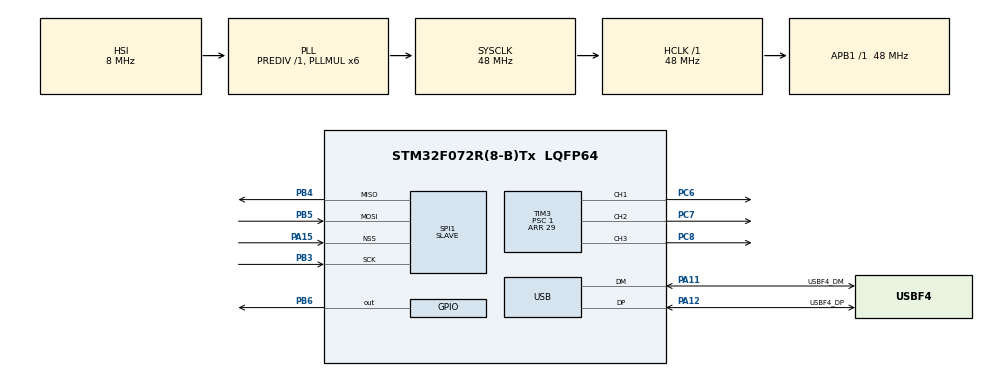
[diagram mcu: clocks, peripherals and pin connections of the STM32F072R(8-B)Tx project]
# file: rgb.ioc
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Dma.Request0=SPI1_TX
Dma.SPI1_TX.0.Direction=DMA_MEMORY_TO_PERIPH
Dma.SPI1_TX.0.Instance=DMA1_Channel3
Dma.SPI1_TX.0.MemDataAlignment=DMA_MDATAALIGN_BYTE
Dma.SPI1_TX.0.MemInc=DMA_MINC_ENABLE
Dma.SPI1_TX.0.Mode=DMA_NORMAL
Dma.SPI1_TX.0.PeriphDataAlignment=DMA_PDATAALIGN_BYTE
Dma.SPI1_TX.0.PeriphInc=DMA_PINC_DISABLE
Dma.SPI1_TX.0.Priority=DMA_PRIORITY_LOW
Mcu.Family=STM32F0
Mcu.Name=STM32F072R(8-B)Tx
Mcu.Package=LQFP64
NVIC.DMA1_Channel2_3_IRQn=true\:0\:0\:false\:false\:true\:false
NVIC.USB_IRQn=true\:0\:0\:false\:false\:true\:false
PA11.GPIO_Label=USBF4_DM
PA11.Mode=Device
PA11.Signal=USB_DM
PA12.GPIO_Label=USBF4_DP
PA12.Mode=Device
PA12.Signal=USB_DP
PA13.GPIO_Label=SWDIO
PA13.Mode=Serial_Wire
PA13.Signal=SYS_SWDIO
PA14.GPIO_Label=SWCLK
PA14.Mode=Serial_Wire
PA14.Signal=SYS_SWCLK
PA15.GPIO_PuPd=GPIO_PULLDOWN
PA15.Mode=NSS_Signal_Hard_Input
PA15.Signal=SPI1_NSS
PB3.Mode=Full_Duplex_Slave
PB3.Signal=SPI1_SCK
PB4.Mode=Full_Duplex_Slave
PB4.Signal=SPI1_MISO
PB5.Mode=Full_Duplex_Slave
PB5.Signal=SPI1_MOSI
PB6.Signal=GPIO_Output
PC6.Signal=S_TIM3_CH1
PC7.Signal=S_TIM3_CH2
PC8.Signal=S_TIM3_CH3
ProjectManager.HeapSize=0x1000
ProjectManager.StackSize=0x1000
ProjectManager.TargetToolchain=TrueSTUDIO
RCC.AHBFreq_Value=48000000
RCC.APB1Freq_Value=48000000
RCC.APB1TimFreq_Value=48000000
RCC.HCLKFreq_Value=48000000
RCC.PLLMUL=RCC_PLL_MUL6
RCC.SYSCLKFreq_VALUE=48000000
RCC.SYSCLKSource=RCC_SYSCLKSOURCE_PLLCLK
SH.S_TIM3_CH1.0=TIM3_CH1,PWM Generation1 CH1
SH.S_TIM3_CH2.0=TIM3_CH2,PWM Generation2 CH2
SH.S_TIM3_CH3.0=TIM3_CH3,PWM Generation3 CH3
SPI1.Direction=SPI_DIRECTION_2LINES
SPI1.Mode=SPI_MODE_SLAVE
SPI1.VirtualNSS=VM_NSSHARD
SPI1.VirtualType=VM_SLAVE
TIM3.Channel-PWM\ Generation1\ CH1=TIM_CHANNEL_1
TIM3.Channel-PWM\ Generation2\ CH2=TIM_CHANNEL_2
TIM3.Channel-PWM\ Generation3\ CH3=TIM_CHANNEL_3
TIM3.Period=29
TIM3.Prescaler=1
TIM3.Pulse-PWM\ Generation1\ CH1=14
TIM3.Pulse-PWM\ Generation2\ CH2=8
TIM3.Pulse-PWM\ Generation3\ CH3=22
USB.phy_itface=PCD_PHY_EMBEDDED
USB.speed=PCD_SPEED_FULL
USB_DEVICE.CLASS_NAME_FS=CDC
USB_DEVICE.VirtualMode=Cdc
USB_DEVICE.VirtualModeFS=Cdc_FS
VP_TIM3_VS_ClockSourceINT.Mode=Internal
VP_USB_DEVICE_VS_USB_DEVICE_CDC_FS.Mode=CDC_FS
board=32F072BDISCOVERY

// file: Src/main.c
/**
  ******************************************************************************
  * @file           : main.c
  * @brief          : Main program body
  ******************************************************************************
  * This notice applies to any and all portions of this file
  * that are not between comment pairs USER CODE BEGIN and
  * USER CODE END. Other portions of this file, whether
  * inserted by the user or by software development tools
  * are owned by their respective copyright owners.
  *
  * Copyright (c) 2019 STMicroelectronics International N.V.
  * All rights reserved.
  *
  * Redistribution and use in source and binary forms, with or without
  * modification, are permitted, provided that the following conditions are met:
  *
  * 1. Redistribution of source code must retain the above copyright notice,
  *    this list of conditions and the following disclaimer.
  * 2. Redistributions in binary form must reproduce the above copyright notice,
  *    this list of conditions and the following disclaimer in the documentation
  *    and/or other materials provided with the distribution.
  * 3. Neither the name of STMicroelectronics nor the names of other
  *    contributors to this software may be used to endorse or promote products
  *    derived from this software without specific written permission.
  * 4. This software, including modifications and/or derivative works of this
  *    software, must execute solely and exclusively on microcontroller or
  *    microprocessor devices manufactured by or for STMicroelectronics.
  * 5. Redistribution and use of this software other than as permitted under
  *    this license is void and will automatically terminate your rights under
  *    this license.
  *
  * THIS SOFTWARE IS PROVIDED BY STMICROELECTRONICS AND CONTRIBUTORS "AS IS"
  * AND ANY EXPRESS, IMPLIED OR STATUTORY WARRANTIES, INCLUDING, BUT NOT
  * LIMITED TO, THE IMPLIED WARRANTIES OF MERCHANTABILITY, FITNESS FOR A
  * PARTICULAR PURPOSE AND NON-INFRINGEMENT OF THIRD PARTY INTELLECTUAL PROPERTY
  * RIGHTS ARE DISCLAIMED TO THE FULLEST EXTENT PERMITTED BY LAW. IN NO EVENT
  * SHALL STMICROELECTRONICS OR CONTRIBUTORS BE LIABLE FOR ANY DIRECT, INDIRECT,
  * INCIDENTAL, SPECIAL, EXEMPLARY, OR CONSEQUENTIAL DAMAGES (INCLUDING, BUT NOT
  * LIMITED TO, PROCUREMENT OF SUBSTITUTE GOODS OR SERVICES; LOSS OF USE, DATA,
  * OR PROFITS; OR BUSINESS INTERRUPTION) HOWEVER CAUSED AND ON ANY THEORY OF
  * LIABILITY, WHETHER IN CONTRACT, STRICT LIABILITY, OR TORT (INCLUDING
  * NEGLIGENCE OR OTHERWISE) ARISING IN ANY WAY OUT OF THE USE OF THIS SOFTWARE,
  * EVEN IF ADVISED OF THE POSSIBILITY OF SUCH DAMAGE.
  *
  ******************************************************************************
  */
#include "main.h"
#include "stm32f0xx_hal.h"
#include "usb_device.h"

/* USER CODE BEGIN Includes */
#include "ws2812_if.h"
/* USER CODE END Includes */

SPI_HandleTypeDef hspi1;
DMA_HandleTypeDef hdma_spi1_tx;

TIM_HandleTypeDef htim3;

/* USER CODE BEGIN PV */
/* Private variables ---------------------------------------------------------*/

/* USER CODE END PV */

void SystemClock_Config(void);
static void MX_GPIO_Init(void);
static void MX_DMA_Init(void);
static void MX_SPI1_Init(void);
static void MX_TIM3_Init(void);

void HAL_TIM_MspPostInit(TIM_HandleTypeDef *htim);

/* USER CODE BEGIN PFP */
/* Private function prototypes -----------------------------------------------*/

  /* USER CODE END DMA1_Channel2_3_IRQn 0 */

  /* USER CODE BEGIN DMA1_Channel2_3_IRQn 1 */

  /* USER CODE END DMA1_Channel2_3_IRQn 1 */

/* USER CODE END PFP */

int main(void)
{

  /* MCU Configuration----------------------------------------------------------*/

  /* Reset of all peripherals, Initializes the Flash interface and the Systick. */
  HAL_Init();

  /* Configure the system clock */
  SystemClock_Config();

  /* Initialize all configured peripherals */
  MX_GPIO_Init();
  MX_DMA_Init();
  MX_SPI1_Init();
  MX_TIM3_Init();
  MX_USB_DEVICE_Init();
  /* USER CODE BEGIN 2 */
  WS2812_Cfg();
  /* USER CODE END 2 */

  /* Infinite loop */
  /* USER CODE BEGIN WHILE */
  while (1)
  {
	  WS2812_Main();
  /* USER CODE END WHILE */

  }

}

void SystemClock_Config(void)
{

  RCC_OscInitTypeDef RCC_OscInitStruct;
  RCC_ClkInitTypeDef RCC_ClkInitStruct;
  RCC_PeriphCLKInitTypeDef PeriphClkInit;

    /**Initializes the CPU, AHB and APB busses clocks
    */
  RCC_OscInitStruct.OscillatorType = RCC_OSCILLATORTYPE_HSI|RCC_OSCILLATORTYPE_HSI48;
  RCC_OscInitStruct.HSIState = RCC_HSI_ON;
  RCC_OscInitStruct.HSI48State = RCC_HSI48_ON;
  RCC_OscInitStruct.HSICalibrationValue = 16;
  RCC_OscInitStruct.PLL.PLLState = RCC_PLL_ON;
  RCC_OscInitStruct.PLL.PLLSource = RCC_PLLSOURCE_HSI;
  RCC_OscInitStruct.PLL.PLLMUL = RCC_PLL_MUL6;
  RCC_OscInitStruct.PLL.PREDIV = RCC_PREDIV_DIV1;
  if (HAL_RCC_OscConfig(&RCC_OscInitStruct) != HAL_OK)
  {
    _Error_Handler(__FILE__, __LINE__);
  }

    /**Initializes the CPU, AHB and APB busses clocks
    */
  RCC_ClkInitStruct.ClockType = RCC_CLOCKTYPE_HCLK|RCC_CLOCKTYPE_SYSCLK
                              |RCC_CLOCKTYPE_PCLK1;
  RCC_ClkInitStruct.SYSCLKSource = RCC_SYSCLKSOURCE_PLLCLK;
  RCC_ClkInitStruct.AHBCLKDivider = RCC_SYSCLK_DIV1;
  RCC_ClkInitStruct.APB1CLKDivider = RCC_HCLK_DIV1;

  if (HAL_RCC_ClockConfig(&RCC_ClkInitStruct, FLASH_LATENCY_1) != HAL_OK)
  {
    _Error_Handler(__FILE__, __LINE__);
  }

  PeriphClkInit.PeriphClockSelection = RCC_PERIPHCLK_USB;
  PeriphClkInit.UsbClockSelection = RCC_USBCLKSOURCE_HSI48;

  if (HAL_RCCEx_PeriphCLKConfig(&PeriphClkInit) != HAL_OK)
  {
    _Error_Handler(__FILE__, __LINE__);
  }

    /**Configure the Systick interrupt time
    */
  HAL_SYSTICK_Config(HAL_RCC_GetHCLKFreq()/1000);

    /**Configure the Systick
    */
  HAL_SYSTICK_CLKSourceConfig(SYSTICK_CLKSOURCE_HCLK);

  /* SysTick_IRQn interrupt configuration */
  HAL_NVIC_SetPriority(SysTick_IRQn, 0, 0);
}

/* SPI1 init function */
static void MX_SPI1_Init(void)
{

  /* SPI1 parameter configuration*/
  hspi1.Instance = SPI1;
  hspi1.Init.Mode = SPI_MODE_SLAVE;
  hspi1.Init.Direction = SPI_DIRECTION_2LINES;
  hspi1.Init.DataSize = SPI_DATASIZE_8BIT;
  hspi1.Init.CLKPolarity = SPI_POLARITY_HIGH;
  hspi1.Init.CLKPhase = SPI_PHASE_1EDGE;
  hspi1.Init.NSS = SPI_NSS_HARD_INPUT;
  hspi1.Init.FirstBit = SPI_FIRSTBIT_MSB;
  hspi1.Init.TIMode = SPI_TIMODE_DISABLE;
  hspi1.Init.CRCCalculation = SPI_CRCCALCULATION_DISABLE;
  hspi1.Init.CRCPolynomial = 7;
  hspi1.Init.CRCLength = SPI_CRC_LENGTH_DATASIZE;
  hspi1.Init.NSSPMode = SPI_NSS_PULSE_DISABLE;
  if (HAL_SPI_Init(&hspi1) != HAL_OK)
  {
    _Error_Handler(__FILE__, __LINE__);
  }

}

/* TIM3 init function */
static void MX_TIM3_Init(void)
{

  TIM_ClockConfigTypeDef sClockSourceConfig;
  TIM_MasterConfigTypeDef sMasterConfig;
  TIM_OC_InitTypeDef sConfigOC;

  htim3.Instance = TIM3;
  htim3.Init.Prescaler = 1;
  htim3.Init.CounterMode = TIM_COUNTERMODE_UP;
  htim3.Init.Period = 29;
  htim3.Init.ClockDivision = TIM_CLOCKDIVISION_DIV1;
  htim3.Init.AutoReloadPreload = TIM_AUTORELOAD_PRELOAD_DISABLE;
  if (HAL_TIM_Base_Init(&htim3) != HAL_OK)
  {
    _Error_Handler(__FILE__, __LINE__);
  }

  sClockSourceConfig.ClockSource = TIM_CLOCKSOURCE_INTERNAL;
  if (HAL_TIM_ConfigClockSource(&htim3, &sClockSourceConfig) != HAL_OK)
  {
    _Error_Handler(__FILE__, __LINE__);
  }

  if (HAL_TIM_PWM_Init(&htim3) != HAL_OK)
  {
    _Error_Handler(__FILE__, __LINE__);
  }

  sMasterConfig.MasterOutputTrigger = TIM_TRGO_RESET;
  sMasterConfig.MasterSlaveMode = TIM_MASTERSLAVEMODE_DISABLE;
  if (HAL_TIMEx_MasterConfigSynchronization(&htim3, &sMasterConfig) != HAL_OK)
  {
    _Error_Handler(__FILE__, __LINE__);
  }

  sConfigOC.OCMode = TIM_OCMODE_PWM1;
  sConfigOC.Pulse = 14;
  sConfigOC.OCPolarity = TIM_OCPOLARITY_HIGH;
  sConfigOC.OCFastMode = TIM_OCFAST_DISABLE;
  if (HAL_TIM_PWM_ConfigChannel(&htim3, &sConfigOC, TIM_CHANNEL_1) != HAL_OK)
  {
    _Error_Handler(__FILE__, __LINE__);
  }

  sConfigOC.Pulse = 8;
  if (HAL_TIM_PWM_ConfigChannel(&htim3, &sConfigOC, TIM_CHANNEL_2) != HAL_OK)
  {
    _Error_Handler(__FILE__, __LINE__);
  }

  sConfigOC.Pulse = 22;
  if (HAL_TIM_PWM_ConfigChannel(&htim3, &sConfigOC, TIM_CHANNEL_3) != HAL_OK)
  {
    _Error_Handler(__FILE__, __LINE__);
  }

  HAL_TIM_MspPostInit(&htim3);

}

static void MX_DMA_Init(void)
{
  /* DMA controller clock enable */
  __HAL_RCC_DMA1_CLK_ENABLE();

  /* DMA interrupt init */
  /* DMA1_Channel2_3_IRQn interrupt configuration */
  HAL_NVIC_SetPriority(DMA1_Channel2_3_IRQn, 0, 0);
  HAL_NVIC_EnableIRQ(DMA1_Channel2_3_IRQn);

}

/** Configure pins as
        * Analog
        * Input
        * Output
        * EVENT_OUT
        * EXTI
*/
static void MX_GPIO_Init(void)
{

  GPIO_InitTypeDef GPIO_InitStruct;

  /* GPIO Ports Clock Enable */
  __HAL_RCC_GPIOC_CLK_ENABLE();
  __HAL_RCC_GPIOA_CLK_ENABLE();
  __HAL_RCC_GPIOB_CLK_ENABLE();

  /*Configure GPIO pin Output Level */
  HAL_GPIO_WritePin(GPIOB, GPIO_PIN_6, GPIO_PIN_RESET);

  /*Configure GPIO pin : PB6 */
  GPIO_InitStruct.Pin = GPIO_PIN_6;
  GPIO_InitStruct.Mode = GPIO_MODE_OUTPUT_PP;
  GPIO_InitStruct.Pull = GPIO_NOPULL;
  GPIO_InitStruct.Speed = GPIO_SPEED_FREQ_LOW;
  HAL_GPIO_Init(GPIOB, &GPIO_InitStruct);

}

void _Error_Handler(char *file, int line)
{
  while(1)
  {
  }
}

/************************ (C) COPYRIGHT STMicroelectronics *****END OF FILE****/
